CM_ "IMPORT _honda_2017.dbc"
CM_ "IMPORT _comma.dbc"

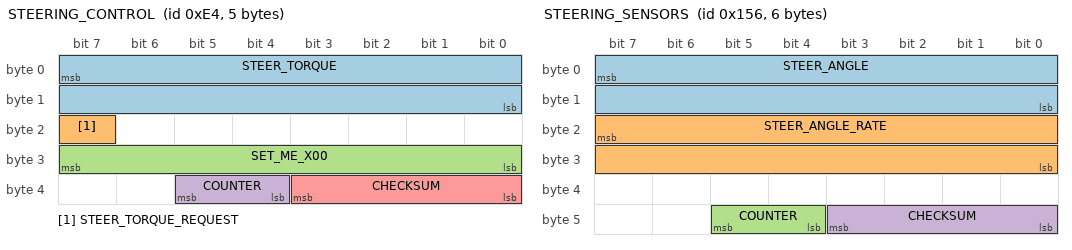
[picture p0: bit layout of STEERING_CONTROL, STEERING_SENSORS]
BO_ 228 STEERING_CONTROL: 5 ADAS
 SG_ STEER_TORQUE : 7|16@0- (1,0) [-3840|3840] "" EPS
 SG_ STEER_TORQUE_REQUEST : 23|1@0+ (1,0) [0|1] "" EPS
 SG_ SET_ME_X00 : 31|8@0+ (1,0) [0|0] "" EPS
 SG_ COUNTER : 37|2@0+ (1,0) [0|3] "" EPS
 SG_ CHECKSUM : 35|4@0+ (1,0) [0|3] "" EPS

BO_ 316 GAS_PEDAL: 8 PCM
 SG_ CAR_GAS : 39|8@0+ (1,0) [0|255] "" EON

BO_ 342 STEERING_SENSORS: 6 EPS
 SG_ STEER_ANGLE : 7|16@0- (-0.1,0) [-500|500] "deg" EON
 SG_ STEER_ANGLE_RATE : 23|16@0- (1,0) [-3000|3000] "deg/s" EON
 SG_ COUNTER : 45|2@0+ (1,0) [0|3] "" EON
 SG_ CHECKSUM : 43|4@0+ (1,0) [0|3] "" EON

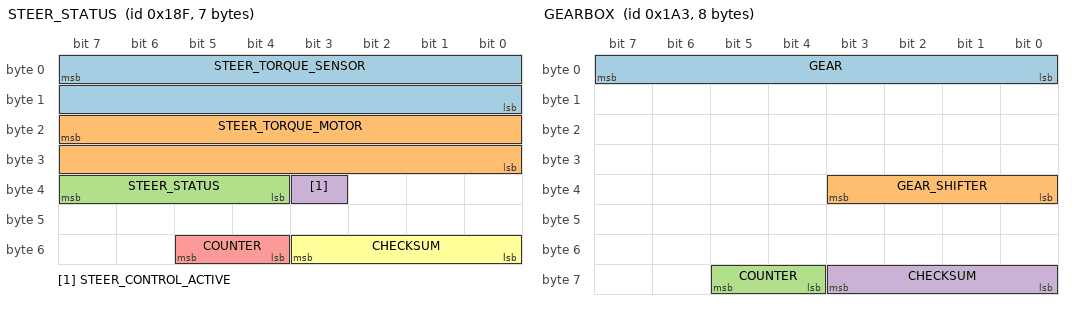
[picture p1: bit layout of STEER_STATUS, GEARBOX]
BO_ 399 STEER_STATUS: 7 EPS
 SG_ STEER_TORQUE_SENSOR : 7|16@0- (1,0) [-31000|31000] "tbd" EON
 SG_ STEER_TORQUE_MOTOR : 23|16@0- (1,0) [-31000|31000] "tbd" EON
 SG_ STEER_STATUS : 39|4@0+ (1,0) [0|15] "" EON
 SG_ STEER_CONTROL_ACTIVE : 35|1@0+ (1,0) [0|1] "" EON
 SG_ COUNTER : 53|2@0+ (1,0) [0|3] "" EON
 SG_ CHECKSUM : 51|4@0+ (1,0) [0|3] "" EON

BO_ 419 GEARBOX: 8 PCM
 SG_ GEAR : 7|8@0+ (1,0) [0|256] "" EON
 SG_ GEAR_SHIFTER : 35|4@0+ (1,0) [0|15] "" EON
 SG_ COUNTER : 61|2@0+ (1,0) [0|3] "" EON
 SG_ CHECKSUM : 59|4@0+ (1,0) [0|3] "" EON

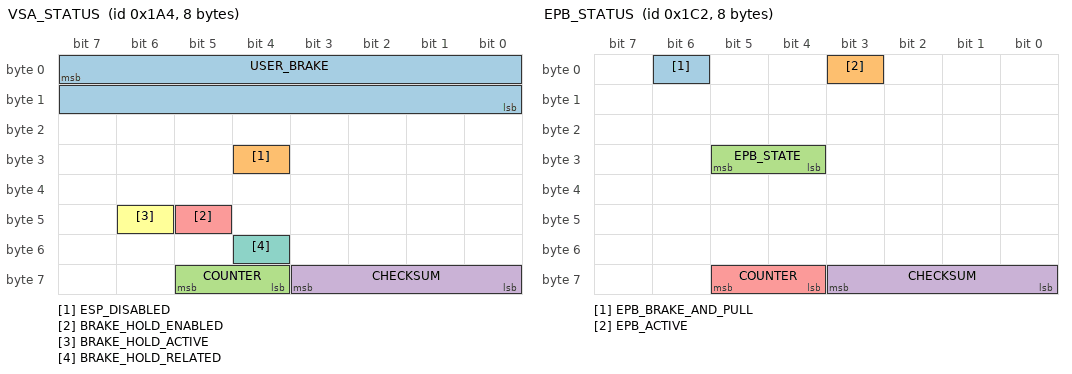
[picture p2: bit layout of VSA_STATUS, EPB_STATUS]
BO_ 420 VSA_STATUS: 8 VSA
 SG_ USER_BRAKE : 7|16@0+ (0.015625,-1.609375) [0|1000] "" EON
 SG_ ESP_DISABLED : 28|1@0+ (1,0) [0|1] "" EON
 SG_ COUNTER : 61|2@0+ (1,0) [0|3] "" EON
 SG_ CHECKSUM : 59|4@0+ (1,0) [0|3] "" EON
 SG_ BRAKE_HOLD_ENABLED : 45|1@0+ (1,0) [0|1] "" XXX
 SG_ BRAKE_HOLD_ACTIVE : 46|1@0+ (1,0) [0|1] "" XXX
 SG_ BRAKE_HOLD_RELATED : 52|1@0+ (1,0) [0|1] "" XXX

BO_ 450 EPB_STATUS: 8 XXX
 SG_ EPB_BRAKE_AND_PULL : 6|1@0+ (1,0) [0|1] "" XXX
 SG_ EPB_ACTIVE : 3|1@0+ (1,0) [0|1] "" XXX
 SG_ EPB_STATE : 29|2@0+ (1,0) [0|1] "" XXX
 SG_ CHECKSUM : 59|4@0+ (1,0) [0|15] "" XXX
 SG_ COUNTER : 61|2@0+ (1,0) [0|3] "" XXX

BO_ 506 BRAKE_COMMAND: 8 ADAS
 SG_ COMPUTER_BRAKE : 7|10@0+ (1,0) [0|1] "" EBCM
 SG_ ZEROS_BOH : 13|5@0+ (1,0) [0|1] "" EBCM
 SG_ BRAKE_PUMP_REQUEST : 8|1@0+ (1,0) [0|1] "" EBCM
 SG_ CRUISE_BOH2 : 23|3@0+ (1,0) [0|1] "" EBCM
 SG_ CRUISE_OVERRIDE : 20|1@0+ (1,0) [0|1] "" EBCM
 SG_ CRUISE_BOH3 : 19|1@0+ (1,0) [0|1] "" EBCM
 SG_ CRUISE_FAULT_CMD : 18|1@0+ (1,0) [0|1] "" EBCM
 SG_ CRUISE_CANCEL_CMD : 17|1@0+ (1,0) [0|1] "" EBCM
 SG_ COMPUTER_BRAKE_REQUEST : 16|1@0+ (1,0) [0|1] "" EBCM
 SG_ SET_ME_0X80 : 31|8@0+ (1,0) [0|1] "" EBCM
 SG_ BRAKE_LIGHTS : 39|1@0+ (1,0) [0|1] "" EBCM
 SG_ CRUISE_STATES : 38|7@0+ (1,0) [0|1] "" EBCM
 SG_ CHIME : 47|3@0+ (1,0) [0|7] "" EBCM
 SG_ ZEROS_BOH6 : 44|1@0+ (1,0) [0|1] "" EBCM
 SG_ FCW : 43|2@0+ (1,0) [0|3] "" EBCM
 SG_ ZEROS_BOH4 : 55|8@0+ (1,0) [0|0] "" EBCM
 SG_ COUNTER : 61|2@0+ (1,0) [0|3] "" EBCM
 SG_ CHECKSUM : 59|4@0+ (1,0) [0|15] "" EBCM

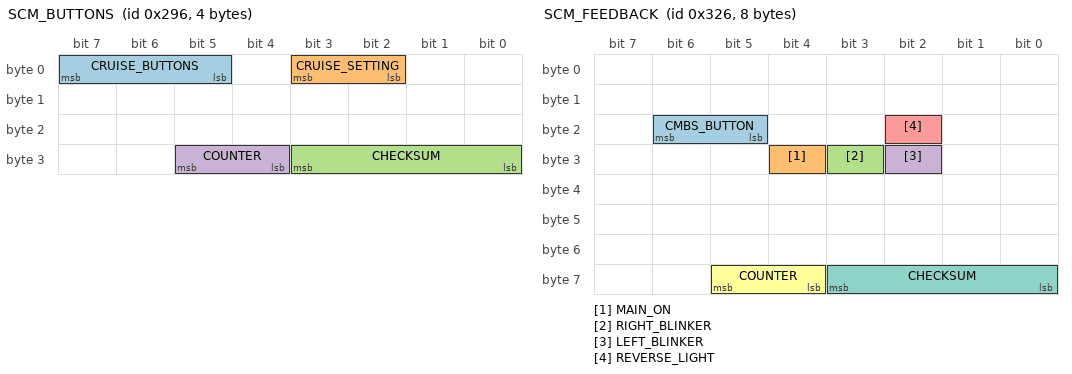
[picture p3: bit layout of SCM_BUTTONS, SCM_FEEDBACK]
BO_ 662 SCM_BUTTONS: 4 SCM
 SG_ CRUISE_BUTTONS : 7|3@0+ (1,0) [0|7] "" EON
 SG_ CRUISE_SETTING : 3|2@0+ (1,0) [0|3] "" EON
 SG_ CHECKSUM : 27|4@0+ (1,0) [0|3] "" EON
 SG_ COUNTER : 29|2@0+ (1,0) [0|3] "" EON

BO_ 806 SCM_FEEDBACK: 8 SCM
 SG_ CMBS_BUTTON : 22|2@0+ (1,0) [0|3] "" EON
 SG_ MAIN_ON : 28|1@0+ (1,0) [0|1] "" EON
 SG_ RIGHT_BLINKER : 27|1@0+ (1,0) [0|1] "" EON
 SG_ LEFT_BLINKER : 26|1@0+ (1,0) [0|1] "" EON
 SG_ REVERSE_LIGHT : 18|1@0+ (1,0) [0|1] "" EON
 SG_ COUNTER : 61|2@0+ (1,0) [0|3] "" EON
 SG_ CHECKSUM : 59|4@0+ (1,0) [0|3] "" EON

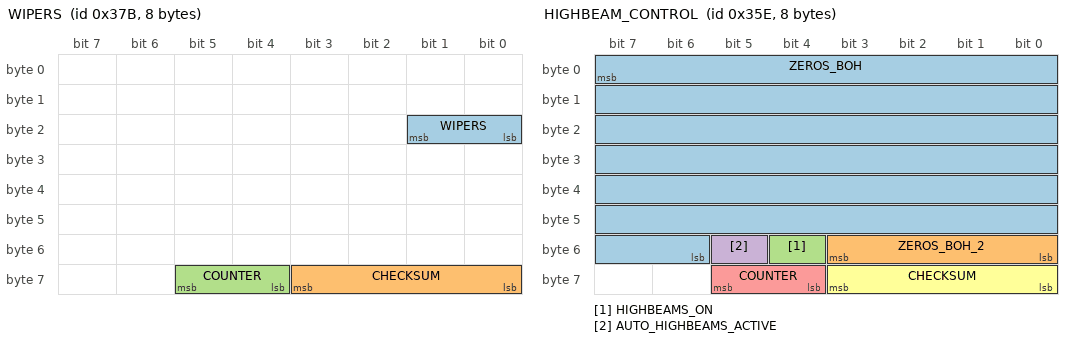
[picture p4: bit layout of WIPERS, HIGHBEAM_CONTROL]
BO_ 891 WIPERS: 8 XXX
 SG_ WIPERS : 17|2@0+ (1,0) [0|3] "" EON
 SG_ CHECKSUM : 59|4@0+ (1,0) [0|3] "" EON
 SG_ COUNTER : 61|2@0+ (1,0) [0|3] "" EON

BO_ 862 HIGHBEAM_CONTROL: 8 ADAS
 SG_ ZEROS_BOH : 7|50@0+ (1,0) [0|127] "" BDY
 SG_ ZEROS_BOH_2 : 48|4@1+ (1,0) [0|15] "" XXX
 SG_ HIGHBEAMS_ON : 52|1@0+ (1,0) [0|1] "" XXX
 SG_ AUTO_HIGHBEAMS_ACTIVE : 53|1@0+ (1,0) [0|1] "" XXX
 SG_ COUNTER : 61|2@0+ (1,0) [0|3] "" XXX
 SG_ CHECKSUM : 59|4@0+ (1,0) [0|15] "" XXX

BO_ 927 RADAR_HUD: 8 ADAS
 SG_ ZEROS_BOH : 7|17@0+ (1,0) [0|127] "" BDY
 SG_ APPLY_BRAKES_FOR_CANC : 23|1@0+ (1,0) [0|15] "" BDY
 SG_ ZEROS_BOH2 : 31|8@0+ (1,0) [0|127] "" BDY
 SG_ RESUME_INSTRUCTION : 21|1@0+ (1,0) [0|15] "" BDY
 SG_ ACC_ALERTS : 20|5@0+ (1,0) [0|15] "" BDY
 SG_ LEAD_SPEED : 39|9@0+ (1,0) [0|127] "" BDY
 SG_ LEAD_STATE : 46|3@0+ (1,0) [0|127] "" BDY
 SG_ LEAD_DISTANCE : 43|5@0+ (1,0) [0|31] "" BDY
 SG_ ZEROS_BOH3 : 54|7@0+ (1,0) [0|127] "" BDY
 SG_ COUNTER : 61|2@0+ (1,0) [0|3] "" BDY
 SG_ CHECKSUM : 59|4@0+ (1,0) [0|3] "" BDY

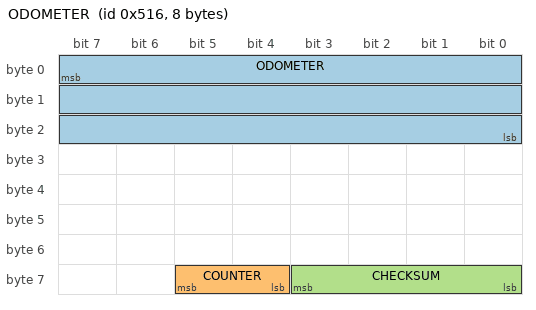
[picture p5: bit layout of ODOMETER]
BO_ 1302 ODOMETER: 8 XXX
 SG_ ODOMETER : 7|24@0+ (1,0) [0|16777215] "km" EON
 SG_ COUNTER : 61|2@0+ (1,0) [0|3] "" EON
 SG_ CHECKSUM : 59|4@0+ (1,0) [0|3] "" EON

CM_ SG_ 419 GEAR "10 = reverse, 11 = transition";
CM_ SG_ 420 BRAKE_HOLD_RELATED "On when Brake Hold engaged";
CM_ SG_ 780 CRUISE_SPEED "255 = no speed";
CM_ SG_ 804 CRUISE_SPEED_PCM "255 = no speed";
CM_ SG_ 806 REVERSE_LIGHT "Might be reverse gear selected and not the lights";
CM_ SG_ 829 BEEP "beeps are pleasant, chimes are for warnings etc...";

VAL_ 399 STEER_STATUS 5 "fault" 4 "no_torque_alert_2" 2 "no_torque_alert_1" 0 "normal" ;
VAL_ 419 GEAR_SHIFTER 10 "S" 4 "D" 3 "N" 2 "R" 1 "P" ;
VAL_ 450 EPB_STATE 3 "engaged" 2 "disengaging" 1 "engaging" 0 "disengaged" ;
VAL_ 662 CRUISE_BUTTONS 7 "tbd" 6 "tbd" 5 "tbd" 4 "accel_res" 3 "decel_set" 2 "cancel" 1 "main" 0 "none" ;
VAL_ 662 CRUISE_SETTING 3 "distance_adj" 2 "tbd" 1 "lkas_button" 0 "none" ;
VAL_ 780 HUD_LEAD 3 "no_car" 2 "solid_car" 1 "dashed_car" 0 "no_car" ;
VAL_ 829 BEEP 3 "single_beep" 2 "triple_beep" 1 "repeated_beep" 0 "no_beep" ;
VAL_ 891 WIPERS 4 "High" 2 "Low" 0 "Off" ;
VAL_ 927 ACC_ALERTS 29 "esp_active_acc_canceled" 10 "b_pedal_applied" 9 "speed_too_low" 8 "speed_too_high" 7 "p_brake_applied" 6 "gear_no_d" 5 "seatbelt" 4 "too_steep_downhill" 3 "too_steep_uphill" 2 "too_close" 1 "no_vehicle_ahead" ;
VAL_ 806 CMBS_BUTTON 3 "pressed" 0 "released" ;
VAL_ 891 WIPERS 4 "High" 2 "Low" 0 "Off" ;
VAL_ 927 ACC_ALERTS 29 "esp_active_acc_canceled" 10 "b_pedal_applied" 9 "speed_too_low" 8 "speed_too_high" 7 "p_brake_applied" 6 "gear_no_d" 5 "seatbelt" 4 "too_steep_downhill" 3 "too_steep_uphill" 2 "too_close" 1 "no_vehicle_ahead" ;

CM_ "CHFFR_METRIC 342 STEER_ANGLE STEER_ANGLE 0.36 180; CHFFR_METRIC 380 ENGINE_RPM ENGINE_RPM 1 0; CHFFR_METRIC 804 ENGINE_TEMPERATURE ENGINE_TEMPERATURE 1 0";
